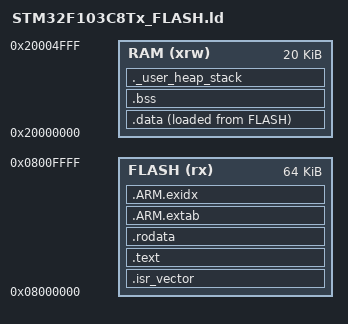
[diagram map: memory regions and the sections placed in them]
/* STM32F103C8T6 - Bluepill */

ENTRY(Reset_Handler)

/* Initial stack pointer: top of SRAM */
_estack = ORIGIN(RAM) + LENGTH(RAM);

/* Minimum heap and stack allocation */
_Min_Heap_Size  = 0x200;  /* 512 bytes */
_Min_Stack_Size = 0x400;  /* 1 KB */

MEMORY
{
    FLASH (rx)  : ORIGIN = 0x08000000, LENGTH = 64K
    RAM   (xrw) : ORIGIN = 0x20000000, LENGTH = 20K
}

SECTIONS
{
    /* Interrupt vector table */
    .isr_vector :
    {
        . = ALIGN(4);
        KEEP(*(.isr_vector))
        . = ALIGN(4);
    } > FLASH

    /* Program code */
    .text :
    {
        . = ALIGN(4);
        *(.text)
        *(.text*)
        *(.glue_7)
        *(.glue_7t)
        *(.eh_frame)

        KEEP(*(.init))
        KEEP(*(.fini))

        . = ALIGN(4);
        _etext = .;
    } > FLASH

    /* Read-only data */
    .rodata :
    {
        . = ALIGN(4);
        *(.rodata)
        *(.rodata*)
        . = ALIGN(4);
    } > FLASH

    /* ARM exception tables */
    .ARM.extab :
    {
        *(.ARM.extab* .gnu.linkonce.armextab.*)
    } > FLASH

    .ARM.exidx :
    {
        __exidx_start = .;
        *(.ARM.exidx* .gnu.linkonce.armexidx.*)
        __exidx_end = .;
    } > FLASH

    /* Initialized global/static variables */
    .data :
    {
        . = ALIGN(4);
        _sdata = .;
        *(.data)
        *(.data*)
        . = ALIGN(4);
        _edata = .;
    } > RAM AT> FLASH

    _sidata = LOADADDR(.data);

    /* Uninitialized global/static variables */
    .bss :
    {
        . = ALIGN(4);
        _sbss = .;
        __bss_start__ = _sbss;

        *(.bss)
        *(.bss*)
        *(COMMON)

        . = ALIGN(4);
        _ebss = .;
        __bss_end__ = _ebss;
    } > RAM

    /* Reserve heap and stack space */
    ._user_heap_stack :
    {
        . = ALIGN(8);
        . = . + _Min_Heap_Size;
        . = . + _Min_Stack_Size;
        . = ALIGN(8);
    } > RAM

    /DISCARD/ :
    {
        *(.note.GNU-stack)
    }
}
